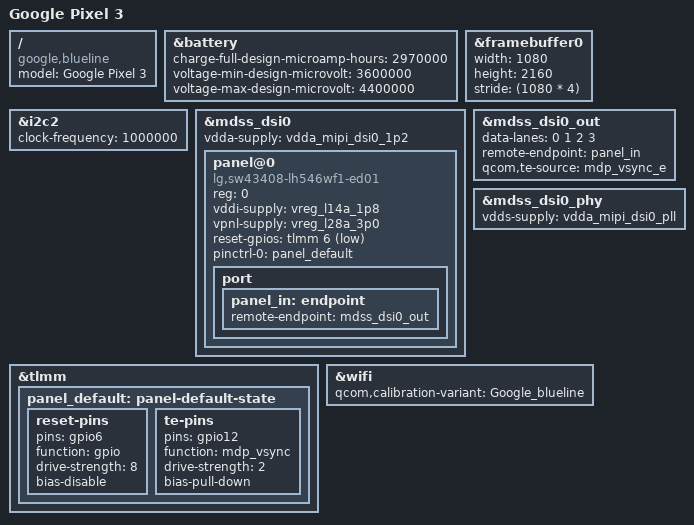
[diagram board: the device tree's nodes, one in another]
// SPDX-License-Identifier: GPL-2.0-only

/dts-v1/;

#include "sdm845-google-common.dtsi"

/ {
	model = "Google Pixel 3";
	compatible = "google,blueline", "qcom,sdm845";
};

&battery {
	charge-full-design-microamp-hours = <2970000>;
	voltage-min-design-microvolt = <3600000>;
	voltage-max-design-microvolt = <4400000>;
};

&framebuffer0 {
	width = <1080>;
	height = <2160>;
	stride = <(1080 * 4)>;
};

&i2c2 {
	clock-frequency = <1000000>;

	status = "okay";

	/* ST,FTS @ 49 */
};

&mdss_dsi0 {
	vdda-supply = <&vdda_mipi_dsi0_1p2>;

	status = "okay";

	panel@0 {
		compatible = "lg,sw43408-lh546wf1-ed01", "lg,sw43408";
		reg = <0>;

		vddi-supply = <&vreg_l14a_1p8>;
		vpnl-supply = <&vreg_l28a_3p0>;

		reset-gpios = <&tlmm 6 GPIO_ACTIVE_LOW>;

		pinctrl-0 = <&panel_default>;
		pinctrl-names = "default";

		port {
			panel_in: endpoint {
				remote-endpoint = <&mdss_dsi0_out>;
			};
		};
	};
};

&mdss_dsi0_out {
	data-lanes = <0 1 2 3>;
	remote-endpoint = <&panel_in>;
	qcom,te-source = "mdp_vsync_e";
};

&mdss_dsi0_phy {
	vdds-supply = <&vdda_mipi_dsi0_pll>;

	status = "okay";
};

&tlmm {
	panel_default: panel-default-state {
		reset-pins {
			pins = "gpio6";
			function = "gpio";
			drive-strength = <8>;
			bias-disable;
		};

		te-pins {
			pins = "gpio12";
			function = "mdp_vsync";
			drive-strength = <2>;
			bias-pull-down;
		};
	};
};

&wifi {
	qcom,calibration-variant = "Google_blueline";
};
